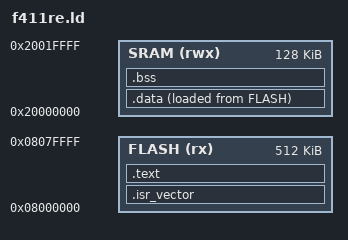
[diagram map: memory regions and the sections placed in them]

ENTRY(Reset_Handler)

MEMORY {
    FLASH(rx) : ORIGIN = 0x08000000, LENGTH = 512K
    SRAM(rwx) : ORIGIN = 0x20000000, LENGTH = 128K
}

_estack = ORIGIN(SRAM) + LENGTH(SRAM);

__max_heap_size = 0x200;
__max_stack_size = 0x400;

SECTIONS {
    .isr_vector :
    {
        . = ALIGN(4);
        KEEP(*(.isr_vector))
    } > FLASH

    .text :
    {
        . = ALIGN(4);
        *(.text)
        *(.rodata)
        . = ALIGN(4);
        _etext = .;
    } > FLASH

    .data :
    {
        . = ALIGN(4);
        _sidata = LOADADDR(.data);
        _sdata = .;
        *(.data)
        . = ALIGN(4);
        _edata = .;
    } > SRAM AT> FLASH

    .bss :
    {
        . = ALIGN(4);
        _sbss = .;
        *(.bss)
        . = ALIGN(4);
        _ebss = .;
    } > SRAM
}
